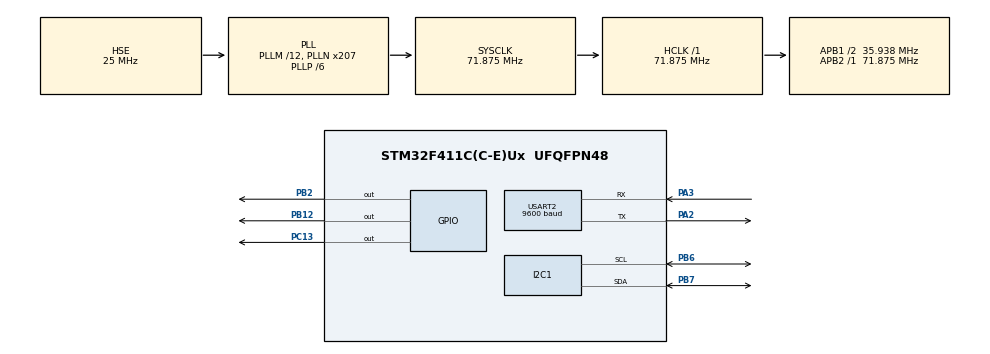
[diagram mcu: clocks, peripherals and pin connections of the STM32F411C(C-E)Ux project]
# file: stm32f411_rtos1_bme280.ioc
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FREERTOS.Events01=myEvent01,Dynamic,NULL
FREERTOS.Tasks01=defaultTask,24,512,StartDefaultTask,Default,NULL,Dynamic,NULL,NULL;task1,24,1024,task1_init,Default,NULL,Dynamic,NULL,NULL;task2,24,1024,task2_init,Default,NULL,Dynamic,NULL,NULL
FREERTOS.configUSE_NEWLIB_REENTRANT=1
Mcu.Family=STM32F4
Mcu.Name=STM32F411C(C-E)Ux
Mcu.Package=UFQFPN48
NVIC.PriorityGroup=NVIC_PRIORITYGROUP_4
NVIC.TIM1_BRK_TIM9_IRQn=true\:15\:0\:false\:false\:true\:false\:false\:true\:true
NVIC.TimeBase=TIM1_BRK_TIM9_IRQn
NVIC.TimeBaseIP=TIM9
PA13.Mode=Serial_Wire
PA13.Signal=SYS_JTMS-SWDIO
PA14.Mode=Serial_Wire
PA14.Signal=SYS_JTCK-SWCLK
PA2.Mode=Asynchronous
PA2.Signal=USART2_TX
PA3.Mode=Asynchronous
PA3.Signal=USART2_RX
PB12.PinState=GPIO_PIN_RESET
PB12.Signal=GPIO_Output
PB2.Signal=GPIO_Output
PB6.Mode=I2C
PB6.Signal=I2C1_SCL
PB7.Mode=I2C
PB7.Signal=I2C1_SDA
PC13-ANTI_TAMP.PinState=GPIO_PIN_RESET
PC13-ANTI_TAMP.Signal=GPIO_Output
PH0\ -\ OSC_IN.Mode=HSE-External-Oscillator
PH0\ -\ OSC_IN.Signal=RCC_OSC_IN
PH1\ -\ OSC_OUT.Mode=HSE-External-Oscillator
PH1\ -\ OSC_OUT.Signal=RCC_OSC_OUT
ProjectManager.HeapSize=0x200
ProjectManager.StackSize=0x400
ProjectManager.TargetToolchain=STM32CubeIDE
RCC.48MHZClocksFreq_Value=86250000
RCC.AHBFreq_Value=71875000
RCC.APB1CLKDivider=RCC_HCLK_DIV2
RCC.APB1Freq_Value=35937500
RCC.APB1TimFreq_Value=71875000
RCC.APB2Freq_Value=71875000
RCC.APB2TimFreq_Value=71875000
RCC.CortexFreq_Value=71875000
RCC.HCLKFreq_Value=71875000
RCC.HSE_VALUE=25000000
RCC.HSI_VALUE=16000000
RCC.LSE_VALUE=32768
RCC.PLLM=12
RCC.PLLN=207
RCC.PLLP=RCC_PLLP_DIV6
RCC.PLLQ=5
RCC.PLLSourceVirtual=RCC_PLLSOURCE_HSE
RCC.SYSCLKFreq_VALUE=71875000
RCC.SYSCLKSource=RCC_SYSCLKSOURCE_PLLCLK
RCC.VCOOutputFreq_Value=431250000
USART2.BaudRate=9600
USART2.VirtualMode=VM_ASYNC
VP_FREERTOS_VS_CMSIS_V2.Mode=CMSIS_V2
VP_SYS_VS_tim9.Mode=TIM9
board=custom

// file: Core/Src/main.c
/* USER CODE BEGIN Header */
/**
  ******************************************************************************
  * @file           : main.c
  * @brief          : Main program body
  ******************************************************************************
  * @attention
  *
  * Copyright (c) 2022 STMicroelectronics.
  * All rights reserved.
  *
  * This software is licensed under terms that can be found in the LICENSE file
  * in the root directory of this software component.
  * If no LICENSE file comes with this software, it is provided AS-IS.
  *
  ******************************************************************************
  */
#include <stdio.h>
#include <string.h>
/* USER CODE END Header */
#include "main.h"
#include "cmsis_os.h"

/* USER CODE BEGIN Includes */
#include "BME280_STM32.h"
/* USER CODE END Includes */

I2C_HandleTypeDef hi2c1;

UART_HandleTypeDef huart2;

/* Definitions for defaultTask */
osThreadId_t defaultTaskHandle;
const osThreadAttr_t defaultTask_attributes = {
  .name = "defaultTask",
  .stack_size = 128 * 4,
  .priority = (osPriority_t) osPriorityNormal,
};
/* Definitions for task1 */
osThreadId_t task1Handle;
const osThreadAttr_t task1_attributes = {
  .name = "task1",
  .stack_size = 1024 * 4,
  .priority = (osPriority_t) osPriorityNormal,
};
/* Definitions for task2 */
osThreadId_t task2Handle;
const osThreadAttr_t task2_attributes = {
  .name = "task2",
  .stack_size = 1024 * 4,
  .priority = (osPriority_t) osPriorityNormal,
};
/* Definitions for myEvent01 */
osEventFlagsId_t myEvent01Handle;
const osEventFlagsAttr_t myEvent01_attributes = {
  .name = "myEvent01"
};

void SystemClock_Config(void);
static void MX_GPIO_Init(void);
static void MX_USART2_UART_Init(void);
static void MX_I2C1_Init(void);
void StartDefaultTask(void *argument);
void task1_init(void *argument);
void task2_init(void *argument);

/* USER CODE BEGIN 0 */
float Temperature, Pressure, Humidity;

/* USER CODE END 0 */

int main(void)
{

  /* MCU Configuration--------------------------------------------------------*/

  /* Reset of all peripherals, Initializes the Flash interface and the Systick. */
  HAL_Init();

  /* Configure the system clock */
  SystemClock_Config();

  /* Initialize all configured peripherals */
  MX_GPIO_Init();
  MX_USART2_UART_Init();
  MX_I2C1_Init();
  /* USER CODE BEGIN 2 */

  BME280_Config(OSRS_2, OSRS_16, OSRS_1, MODE_NORMAL, T_SB_0p5, IIR_16);

  /* USER CODE END 2 */

  /* Init scheduler */
  osKernelInitialize();

  /* Create the thread(s) */
  /* creation of defaultTask */
  defaultTaskHandle = osThreadNew(StartDefaultTask, NULL, &defaultTask_attributes);

  /* creation of task1 */
  task1Handle = osThreadNew(task1_init, NULL, &task1_attributes);

  /* creation of task2 */
  task2Handle = osThreadNew(task2_init, NULL, &task2_attributes);

  /* Create the event(s) */
  /* creation of myEvent01 */
  myEvent01Handle = osEventFlagsNew(&myEvent01_attributes);

  /* Start scheduler */
  osKernelStart();

  /* We should never get here as control is now taken by the scheduler */
  /* Infinite loop */
  while (1)
  {

  }
}

void SystemClock_Config(void)
{
  RCC_OscInitTypeDef RCC_OscInitStruct = {0};
  RCC_ClkInitTypeDef RCC_ClkInitStruct = {0};

  /** Configure the main internal regulator output voltage
  */
  __HAL_RCC_PWR_CLK_ENABLE();
  __HAL_PWR_VOLTAGESCALING_CONFIG(PWR_REGULATOR_VOLTAGE_SCALE1);

  /** Initializes the RCC Oscillators according to the specified parameters
  * in the RCC_OscInitTypeDef structure.
  */
  RCC_OscInitStruct.OscillatorType = RCC_OSCILLATORTYPE_HSE;
  RCC_OscInitStruct.HSEState = RCC_HSE_ON;
  RCC_OscInitStruct.PLL.PLLState = RCC_PLL_ON;
  RCC_OscInitStruct.PLL.PLLSource = RCC_PLLSOURCE_HSE;
  RCC_OscInitStruct.PLL.PLLM = 12;
  RCC_OscInitStruct.PLL.PLLN = 207;
  RCC_OscInitStruct.PLL.PLLP = RCC_PLLP_DIV6;
  RCC_OscInitStruct.PLL.PLLQ = 5;
  if (HAL_RCC_OscConfig(&RCC_OscInitStruct) != HAL_OK)
  {
    Error_Handler();
  }

  /** Initializes the CPU, AHB and APB buses clocks
  */
  RCC_ClkInitStruct.ClockType = RCC_CLOCKTYPE_HCLK|RCC_CLOCKTYPE_SYSCLK
                              |RCC_CLOCKTYPE_PCLK1|RCC_CLOCKTYPE_PCLK2;
  RCC_ClkInitStruct.SYSCLKSource = RCC_SYSCLKSOURCE_PLLCLK;
  RCC_ClkInitStruct.AHBCLKDivider = RCC_SYSCLK_DIV1;
  RCC_ClkInitStruct.APB1CLKDivider = RCC_HCLK_DIV2;
  RCC_ClkInitStruct.APB2CLKDivider = RCC_HCLK_DIV1;

  if (HAL_RCC_ClockConfig(&RCC_ClkInitStruct, FLASH_LATENCY_2) != HAL_OK)
  {
    Error_Handler();
  }
}

static void MX_I2C1_Init(void)
{

  hi2c1.Instance = I2C1;
  hi2c1.Init.ClockSpeed = 100000;
  hi2c1.Init.DutyCycle = I2C_DUTYCYCLE_2;
  hi2c1.Init.OwnAddress1 = 0;
  hi2c1.Init.AddressingMode = I2C_ADDRESSINGMODE_7BIT;
  hi2c1.Init.DualAddressMode = I2C_DUALADDRESS_DISABLE;
  hi2c1.Init.OwnAddress2 = 0;
  hi2c1.Init.GeneralCallMode = I2C_GENERALCALL_DISABLE;
  hi2c1.Init.NoStretchMode = I2C_NOSTRETCH_DISABLE;
  if (HAL_I2C_Init(&hi2c1) != HAL_OK)
  {
    Error_Handler();
  }

}

static void MX_USART2_UART_Init(void)
{

  huart2.Instance = USART2;
  huart2.Init.BaudRate = 9600;
  huart2.Init.WordLength = UART_WORDLENGTH_8B;
  huart2.Init.StopBits = UART_STOPBITS_1;
  huart2.Init.Parity = UART_PARITY_NONE;
  huart2.Init.Mode = UART_MODE_TX_RX;
  huart2.Init.HwFlowCtl = UART_HWCONTROL_NONE;
  huart2.Init.OverSampling = UART_OVERSAMPLING_16;
  if (HAL_UART_Init(&huart2) != HAL_OK)
  {
    Error_Handler();
  }

}

static void MX_GPIO_Init(void)
{
  GPIO_InitTypeDef GPIO_InitStruct = {0};

  /* GPIO Ports Clock Enable */
  __HAL_RCC_GPIOC_CLK_ENABLE();
  __HAL_RCC_GPIOH_CLK_ENABLE();
  __HAL_RCC_GPIOA_CLK_ENABLE();
  __HAL_RCC_GPIOB_CLK_ENABLE();

  /*Configure GPIO pin Output Level */
  HAL_GPIO_WritePin(GPIOC, GPIO_PIN_13, GPIO_PIN_RESET);

  /*Configure GPIO pin Output Level */
  HAL_GPIO_WritePin(GPIOB, GPIO_PIN_2|GPIO_PIN_12, GPIO_PIN_RESET);

  /*Configure GPIO pin : PC13 */
  GPIO_InitStruct.Pin = GPIO_PIN_13;
  GPIO_InitStruct.Mode = GPIO_MODE_OUTPUT_PP;
  GPIO_InitStruct.Pull = GPIO_NOPULL;
  GPIO_InitStruct.Speed = GPIO_SPEED_FREQ_LOW;
  HAL_GPIO_Init(GPIOC, &GPIO_InitStruct);

  /*Configure GPIO pins : PB2 PB12 */
  GPIO_InitStruct.Pin = GPIO_PIN_2|GPIO_PIN_12;
  GPIO_InitStruct.Mode = GPIO_MODE_OUTPUT_PP;
  GPIO_InitStruct.Pull = GPIO_NOPULL;
  GPIO_InitStruct.Speed = GPIO_SPEED_FREQ_LOW;
  HAL_GPIO_Init(GPIOB, &GPIO_InitStruct);

}

void StartDefaultTask(void *argument)
{
  /* USER CODE BEGIN 5 */
  /* Infinite loop */
  for(;;)
  {
	osDelay(pdMS_TO_TICKS(500));
  }
  /* USER CODE END 5 */
}

void task1_init(void *argument)
{
  /* USER CODE BEGIN task1_init */
  /* Infinite loop */
  for(;;)
  {
  osDelay(pdMS_TO_TICKS(500));
  // acquire
  uint8_t Test[] = "Hello World !!!\r\n"; //Data to send
  // release
  HAL_UART_Transmit(&huart2, Test, sizeof(Test), pdMS_TO_TICKS(1000));	// Sending in normal mode
  }
  /* USER CODE END task1_init */
}

void task2_init(void *argument)
{
  /* USER CODE BEGIN task2_init */
  char buffer[128];
  /* Infinite loop */
  for(;;)
  {
	// for I2C Read
	//osDelay(pdMS_TO_TICKS(100));
	  osDelay(pdMS_TO_TICKS(100));
	//acquire
	BME280_Measure();
	// release
	snprintf(buffer, 128, "%f, %f, %f\r\n", Temperature, Humidity, Pressure);
	HAL_UART_Transmit(&huart2, (uint8_t *)buffer, strlen(buffer), pdMS_TO_TICKS(1000));	// Sending in normal mode

  }
  /* USER CODE END task2_init */
}

void HAL_TIM_PeriodElapsedCallback(TIM_HandleTypeDef *htim)
{
  if (htim->Instance == TIM9) {
    HAL_IncTick();
  }
}

void Error_Handler(void)
{
  __disable_irq();
  while (1)
  {
  }
}
